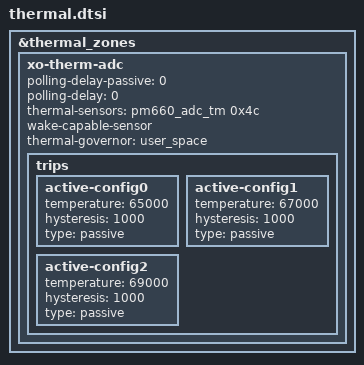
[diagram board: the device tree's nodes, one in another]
/*
 * Copyright (c) 2024, The Linux Foundation. All rights reserved.
 *
 * This program is free software; you can redistribute it and/or modify
 * it under the terms of the GNU General Public License version 2 and
 * only version 2 as published by the Free Software Foundation.
 *
 * This program is distributed in the hope that it will be useful,
 * but WITHOUT ANY WARRANTY; without even the implied warranty of
 * MERCHANTABILITY or FITNESS FOR A PARTICULAR PURPOSE.  See the
 * GNU General Public License for more details.
 */

&thermal_zones {
	xo-therm-adc {
		polling-delay-passive = <0>;
		polling-delay = <0>;
		thermal-sensors = <&pm660_adc_tm 0x4c>;
		wake-capable-sensor;
		thermal-governor = "user_space";

		trips {
			active-config0 {
				temperature = <65000>;
				hysteresis = <1000>;
				type = "passive";
			};

			active-config1 {
				temperature = <67000>;
				hysteresis = <1000>;
				type = "passive";
			};

			active-config2 {
				temperature = <69000>;
				hysteresis = <1000>;
				type = "passive";
			};
		};
	};
};
